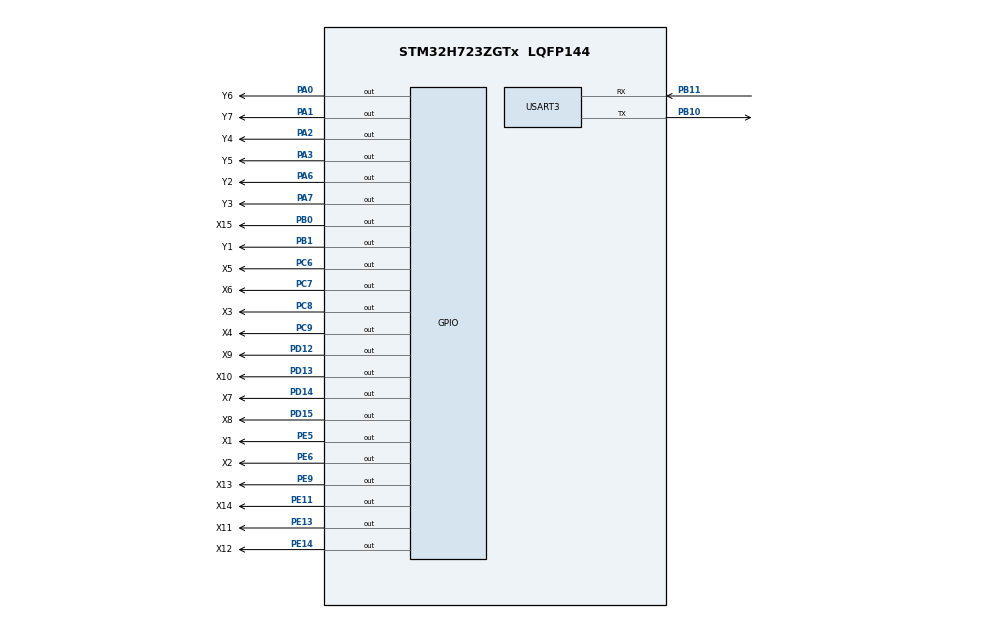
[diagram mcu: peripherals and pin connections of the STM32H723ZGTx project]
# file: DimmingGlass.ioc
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Dma.Request0=USART3_RX
Dma.USART3_RX.0.Direction=DMA_PERIPH_TO_MEMORY
Dma.USART3_RX.0.EventEnable=DISABLE
Dma.USART3_RX.0.FIFOMode=DMA_FIFOMODE_DISABLE
Dma.USART3_RX.0.Instance=DMA1_Stream0
Dma.USART3_RX.0.MemDataAlignment=DMA_MDATAALIGN_BYTE
Dma.USART3_RX.0.MemInc=DMA_MINC_ENABLE
Dma.USART3_RX.0.Mode=DMA_CIRCULAR
Dma.USART3_RX.0.PeriphDataAlignment=DMA_PDATAALIGN_BYTE
Dma.USART3_RX.0.PeriphInc=DMA_PINC_DISABLE
Dma.USART3_RX.0.Polarity=HAL_DMAMUX_REQ_GEN_RISING
Dma.USART3_RX.0.Priority=DMA_PRIORITY_VERY_HIGH
Dma.USART3_RX.0.RequestNumber=1
Dma.USART3_RX.0.SignalID=NONE
Dma.USART3_RX.0.SyncEnable=DISABLE
Dma.USART3_RX.0.SyncPolarity=HAL_DMAMUX_SYNC_NO_EVENT
Dma.USART3_RX.0.SyncRequestNumber=1
Dma.USART3_RX.0.SyncSignalID=NONE
FREERTOS.Tasks01=defaultTask,24,128,StartDefaultTask,Default,NULL,Dynamic,NULL,NULL
Mcu.Family=STM32H7
Mcu.Name=STM32H723ZGTx
Mcu.Package=LQFP144
NVIC.DMA1_Stream0_IRQn=true\:5\:0\:false\:false\:true\:true\:false\:true\:true
NVIC.PriorityGroup=NVIC_PRIORITYGROUP_4
NVIC.TIM1_UP_IRQn=true\:5\:0\:false\:false\:true\:true\:true\:true\:true
NVIC.TIM7_IRQn=true\:15\:0\:false\:false\:true\:false\:false\:true\:true
NVIC.TimeBase=TIM7_IRQn
NVIC.TimeBaseIP=TIM7
NVIC.USART3_IRQn=true\:5\:0\:false\:false\:true\:true\:true\:true\:true
PA0.GPIO_Label=Y6
PA0.Signal=GPIO_Output
PA1.GPIO_Label=Y7
PA1.Signal=GPIO_Output
PA13(JTMS/SWDIO).Mode=Serial_Wire
PA13(JTMS/SWDIO).Signal=DEBUG_JTMS-SWDIO
PA14(JTCK/SWCLK).Mode=Serial_Wire
PA14(JTCK/SWCLK).Signal=DEBUG_JTCK-SWCLK
PA2.GPIO_Label=Y4
PA2.Signal=GPIO_Output
PA3.GPIO_Label=Y5
PA3.Signal=GPIO_Output
PA6.GPIO_Label=Y2
PA6.Signal=GPIO_Output
PA7.GPIO_Label=Y3
PA7.Signal=GPIO_Output
PB0.GPIO_Label=X15
PB0.Signal=GPIO_Output
PB1.GPIO_Label=Y1
PB1.Signal=GPIO_Output
PB10.Mode=Asynchronous
PB10.Signal=USART3_TX
PB11.Mode=Asynchronous
PB11.Signal=USART3_RX
PC6.GPIO_Label=X5
PC6.Signal=GPIO_Output
PC7.GPIO_Label=X6
PC7.Signal=GPIO_Output
PC8.GPIO_Label=X3
PC8.Signal=GPIO_Output
PC9.GPIO_Label=X4
PC9.Signal=GPIO_Output
PD12.GPIO_Label=X9
PD12.Signal=GPIO_Output
PD13.GPIO_Label=X10
PD13.Signal=GPIO_Output
PD14.GPIO_Label=X7
PD14.Signal=GPIO_Output
PD15.GPIO_Label=X8
PD15.Signal=GPIO_Output
PE11.GPIO_Label=X14
PE11.Signal=GPIO_Output
PE13.GPIO_Label=X11
PE13.Signal=GPIO_Output
PE14.GPIO_Label=X12
PE14.Signal=GPIO_Output
PE5.GPIO_Label=X1
PE5.Signal=GPIO_Output
PE6.GPIO_Label=X2
PE6.Signal=GPIO_Output
PE9.GPIO_Label=X13
PE9.Signal=GPIO_Output
PH0-OSC_IN.Mode=HSE-External-Oscillator
PH0-OSC_IN.Signal=RCC_OSC_IN
PH1-OSC_OUT.Mode=HSE-External-Oscillator
PH1-OSC_OUT.Signal=RCC_OSC_OUT
ProjectManager.HeapSize=0x200
ProjectManager.StackSize=0x400
ProjectManager.TargetToolchain=MDK-ARM V5.32
RCC.ADCFreq_Value=16125000
RCC.APB1Freq_Value=120000000
RCC.APB2Freq_Value=120000000
RCC.APB3Freq_Value=120000000
RCC.APB4Freq_Value=120000000
RCC.CortexFreq_Value=480000000
RCC.D1PPRE=RCC_APB3_DIV2
RCC.D2PPRE1=RCC_APB1_DIV2
RCC.D2PPRE2=RCC_APB2_DIV2
RCC.D3PPRE=RCC_APB4_DIV2
RCC.DIVM1=1
RCC.DIVN1=60
RCC.DIVP1=1
RCC.HCLKFreq_Value=240000000
RCC.HPRE=RCC_HCLK_DIV2
RCC.HSE_VALUE=8000000
RCC.PLL2FRACN=0
RCC.PLL3FRACN=0
RCC.PLLFRACN=0
RCC.PLLSourceVirtual=RCC_PLLSOURCE_HSE
RCC.SYSCLKFreq_VALUE=480000000
RCC.SYSCLKSource=RCC_SYSCLKSOURCE_PLLCLK
RCC.USBFreq_Value=240000000
TIM1.AutoReloadPreload=TIM_AUTORELOAD_PRELOAD_ENABLE
TIM1.Period=1000-1
TIM1.Prescaler=240-1
USART3.VirtualMode-Asynchronous=VM_ASYNC
VP_FREERTOS_VS_CMSIS_V2.Mode=CMSIS_V2
VP_SYS_VS_tim7.Mode=TIM7
VP_TIM1_VS_ClockSourceINT.Mode=Internal
board=custom

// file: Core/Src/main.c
/* USER CODE BEGIN Header */
/**
  ******************************************************************************
  * @file           : main.c
  * @brief          : Main program body
  ******************************************************************************
  * @attention
  *
  * Copyright (c) 2026 STMicroelectronics.
  * All rights reserved.
  *
  * This software is licensed under terms that can be found in the LICENSE file
  * in the root directory of this software component.
  * If no LICENSE file comes with this software, it is provided AS-IS.
  *
  ******************************************************************************
  */
/* USER CODE END Header */
#include "main.h"
#include "cmsis_os.h"
#include "dma.h"
#include "tim.h"
#include "usart.h"
#include "gpio.h"

/* USER CODE BEGIN Includes */
#include "app_dimmer.h"
#include "tim.h"   /* htim1：行/列调光 1ms tick 定时器 */
/* USER CODE END Includes */

void SystemClock_Config(void);
static void MPU_Config(void);
void MX_FREERTOS_Init(void);

int main(void)
{

  /* MPU Configuration--------------------------------------------------------*/
  MPU_Config();

  /* MCU Configuration--------------------------------------------------------*/

  /* Reset of all peripherals, Initializes the Flash interface and the Systick. */
  HAL_Init();

  /* Configure the system clock */
  SystemClock_Config();

  /* Initialize all configured peripherals */
  MX_GPIO_Init();
  MX_USART3_UART_Init();
  MX_DMA_Init();
  MX_TIM1_Init();
  /* USER CODE BEGIN 2 */
  /* 调光模块初始化：�?有电极同�? -> 整屏关闭 */
  app_dimmer_init();

  /* 启动 TIM1：每 1ms 触发软件 PWM 一个 tick(PWM=1000/16 ≈ 62.5Hz) */
  HAL_TIM_Base_Start_IT(&htim1);
  /* USER CODE END 2 */

  /* Init scheduler */
  osKernelInitialize();  /* Call init function for freertos objects (in freertos.c) */
  MX_FREERTOS_Init();

  /* Start scheduler */
  osKernelStart();

  /* We should never get here as control is now taken by the scheduler */
  /* Infinite loop */
  while (1)
  {

  }
}

void SystemClock_Config(void)
{
  RCC_OscInitTypeDef RCC_OscInitStruct = {0};
  RCC_ClkInitTypeDef RCC_ClkInitStruct = {0};

  /** Supply configuration update enable
  */
  HAL_PWREx_ConfigSupply(PWR_LDO_SUPPLY);

  /** Configure the main internal regulator output voltage
  */
  __HAL_PWR_VOLTAGESCALING_CONFIG(PWR_REGULATOR_VOLTAGE_SCALE0);

  while(!__HAL_PWR_GET_FLAG(PWR_FLAG_VOSRDY)) {}

  /** Initializes the RCC Oscillators according to the specified parameters
  * in the RCC_OscInitTypeDef structure.
  */
  RCC_OscInitStruct.OscillatorType = RCC_OSCILLATORTYPE_HSE;
  RCC_OscInitStruct.HSEState = RCC_HSE_ON;
  RCC_OscInitStruct.PLL.PLLState = RCC_PLL_ON;
  RCC_OscInitStruct.PLL.PLLSource = RCC_PLLSOURCE_HSE;
  RCC_OscInitStruct.PLL.PLLM = 1;
  RCC_OscInitStruct.PLL.PLLN = 60;
  RCC_OscInitStruct.PLL.PLLP = 1;
  RCC_OscInitStruct.PLL.PLLQ = 2;
  RCC_OscInitStruct.PLL.PLLR = 2;
  RCC_OscInitStruct.PLL.PLLRGE = RCC_PLL1VCIRANGE_3;
  RCC_OscInitStruct.PLL.PLLVCOSEL = RCC_PLL1VCOWIDE;
  RCC_OscInitStruct.PLL.PLLFRACN = 0;
  if (HAL_RCC_OscConfig(&RCC_OscInitStruct) != HAL_OK)
  {
    Error_Handler();
  }

  /** Initializes the CPU, AHB and APB buses clocks
  */
  RCC_ClkInitStruct.ClockType = RCC_CLOCKTYPE_HCLK|RCC_CLOCKTYPE_SYSCLK
                              |RCC_CLOCKTYPE_PCLK1|RCC_CLOCKTYPE_PCLK2
                              |RCC_CLOCKTYPE_D3PCLK1|RCC_CLOCKTYPE_D1PCLK1;
  RCC_ClkInitStruct.SYSCLKSource = RCC_SYSCLKSOURCE_PLLCLK;
  RCC_ClkInitStruct.SYSCLKDivider = RCC_SYSCLK_DIV1;
  RCC_ClkInitStruct.AHBCLKDivider = RCC_HCLK_DIV2;
  RCC_ClkInitStruct.APB3CLKDivider = RCC_APB3_DIV2;
  RCC_ClkInitStruct.APB1CLKDivider = RCC_APB1_DIV2;
  RCC_ClkInitStruct.APB2CLKDivider = RCC_APB2_DIV2;
  RCC_ClkInitStruct.APB4CLKDivider = RCC_APB4_DIV2;

  if (HAL_RCC_ClockConfig(&RCC_ClkInitStruct, FLASH_LATENCY_3) != HAL_OK)
  {
    Error_Handler();
  }
}

/* MPU Configuration */

void MPU_Config(void)
{
  MPU_Region_InitTypeDef MPU_InitStruct = {0};

  /* Disables the MPU */
  HAL_MPU_Disable();

  /** Initializes and configures the Region and the memory to be protected
  */
  MPU_InitStruct.Enable = MPU_REGION_ENABLE;
  MPU_InitStruct.Number = MPU_REGION_NUMBER0;
  MPU_InitStruct.BaseAddress = 0x0;
  MPU_InitStruct.Size = MPU_REGION_SIZE_4GB;
  MPU_InitStruct.SubRegionDisable = 0x87;
  MPU_InitStruct.TypeExtField = MPU_TEX_LEVEL0;
  MPU_InitStruct.AccessPermission = MPU_REGION_NO_ACCESS;
  MPU_InitStruct.DisableExec = MPU_INSTRUCTION_ACCESS_DISABLE;
  MPU_InitStruct.IsShareable = MPU_ACCESS_SHAREABLE;
  MPU_InitStruct.IsCacheable = MPU_ACCESS_NOT_CACHEABLE;
  MPU_InitStruct.IsBufferable = MPU_ACCESS_NOT_BUFFERABLE;

  HAL_MPU_ConfigRegion(&MPU_InitStruct);
  /* Enables the MPU */
  HAL_MPU_Enable(MPU_PRIVILEGED_DEFAULT);

}

void HAL_TIM_PeriodElapsedCallback(TIM_HandleTypeDef *htim)
{
  if (htim->Instance == TIM7) {
    HAL_IncTick();
  }
  /* USER CODE BEGIN Callback 1 */
  if (htim->Instance == TIM1) {
    /* 软件 PWM：TIM1 每 1ms 推进一个 tick，刷新 22 路 GPIO */
    app_dimmer_tick_isr();
  }
  /* USER CODE END Callback 1 */
}

void Error_Handler(void)
{
  __disable_irq();
  while (1)
  {
  }
}
